# nrf5340 register map
Vendor: Nordic Semiconductor; Series: nrf53; File version: 1
CPU: CM33 r0p2, little endian, MPU, FPU, 3 interrupt priority bits
Registers are 32-bit, read-write, reset 0x0 unless marked. A register's access mark holds for its fields unless they carry their own. Offsets are from the block's base; [hi:lo] are bit positions; lines under a group give offsets from that group; {n}, {i} and the like mark numbered series; 'fields as' and 'values as' point back to an identical list.

## M2M_NS — Memory to Memory DMA 0
Base 0x4002E000
Same registers: M2M_S 0x5002E000
0x00 TASKS_START wo — Start DMA transfer
  [0] TASKS_START
    1=Trigger task
0x04 TASKS_STOP wo — Stop DMA transfer
  [0] TASKS_STOP
    1=Trigger task
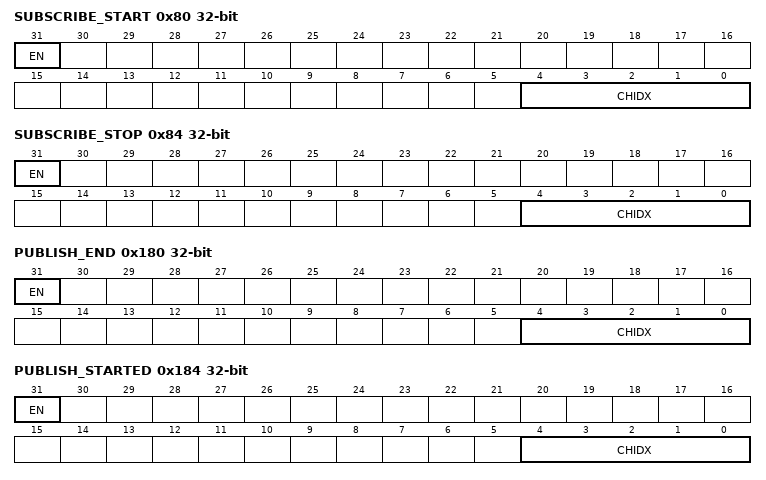
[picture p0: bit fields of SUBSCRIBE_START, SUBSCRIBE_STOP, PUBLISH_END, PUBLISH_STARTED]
0x80 SUBSCRIBE_START — Subscribe configuration for task START
  [31] EN
    0=Disabled (Disable subscription); 1=Enabled (Enable subscription)
  [4:0] CHIDX — Channel that task START will subscribe to
0x84 SUBSCRIBE_STOP — Subscribe configuration for task STOP
  [31] EN
    values as SUBSCRIBE_START.EN
  [4:0] CHIDX — Channel that task STOP will subscribe to
0x100 EVENTS_END — DMA transfer complete
  [0] EVENTS_END
    0=NotGenerated (Event not generated); 1=Generated (Event generated)
0x104 EVENTS_STARTED — DMA transfer started
  [0] EVENTS_STARTED
    values as EVENTS_END.EVENTS_END
0x180 PUBLISH_END — Publish configuration for event END
  [31] EN
    0=Disabled (Disable publishing); 1=Enabled (Enable publishing)
  [4:0] CHIDX — Channel that event END will publish to.
0x184 PUBLISH_STARTED — Publish configuration for event STARTED
  [31] EN
    values as PUBLISH_END.EN
  [4:0] CHIDX — Channel that event STARTED will publish to.
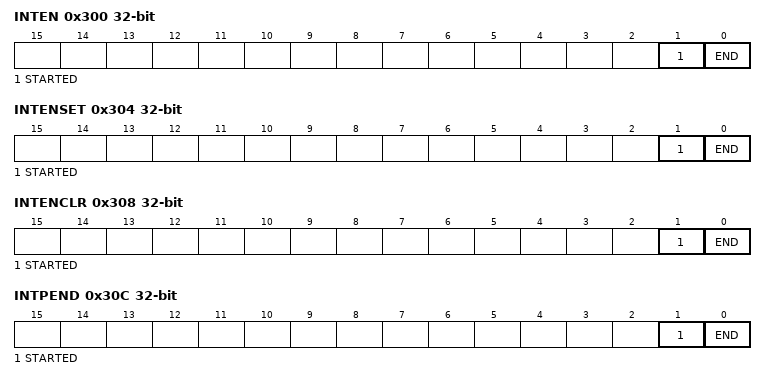
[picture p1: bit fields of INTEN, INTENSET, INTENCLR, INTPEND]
0x300 INTEN — Enable or disable interrupt
  [1] STARTED — Enable or disable interrupt for event STARTED
    0=Disabled; 1=Enabled
  [0] END — Enable or disable interrupt for event END
    0=Disabled; 1=Enabled
0x304 INTENSET — Enable interrupt
  [1] STARTED — Write '1' to enable interrupt for event STARTED
    on read: 0=Disabled (Read: Disabled); 1=Enabled (Read: Enabled) | on write: 1=Set (Enable)
  [0] END — Write '1' to enable interrupt for event END
    values as STARTED
0x308 INTENCLR — Disable interrupt
  [1] STARTED — Write '1' to disable interrupt for event STARTED
    on read: 0=Disabled (Read: Disabled); 1=Enabled (Read: Enabled) | on write: 1=Clear (Disable)
  [0] END — Write '1' to disable interrupt for event END
    values as STARTED
0x30C INTPEND ro — Pending interrupts
  [1] STARTED — Read pending status of interrupt for event STARTED
    on read: 0=NotPending (Read: Not pending); 1=Pending (Read: Pending)
  [0] END — Read pending status of interrupt for event END
    values as STARTED
0x510 IN group — Memory to memory input channel
  0x00 PTR — Data pointer
  0x04 MAXCNT — Maximum number of bytes in input and output buffer
    [15:0] MAXCNT
  0x08 AMOUNT ro — Number of bytes transferred in the last transaction
    [15:0] AMOUNT
  0x0C LIST — EasyDMA list type
    [2:0] LIST — List type
      0=Disabled (Disable EasyDMA list); 1=ArrayList (Use array list)
0x520 OUT group — Memory to memory output channel
  0x00 PTR — Data pointer
  0x04 AMOUNT ro — Number of bytes transferred in the last transaction
    [15:0] AMOUNT
  0x08 LIST — EasyDMA list type
    fields as IN.LIST

## MUTEX_NS — MUTEX 0
Base 0x40030000
Same registers: MUTEX_S 0x50030000
{0x400+4i} MUTEX[{i}] (i=0..15) group — Unspecified
  0x00 GPMUTEX — Description cluster: General purpose mutex register
    [0] GPMUTEX — General Purpose register for MUTEX n
      0=Unlocked (Mutex n is in unlocked state); 1=Locked (Mutex n is in locked state)

## KMU_S — Key Management Unit
Base 0x50080000
0x00 TASKS_PUSH_KEYSLOT wo — Push a key slot over secure APB.
  [0] TASKS_PUSH_KEYSLOT
    1=Trigger task
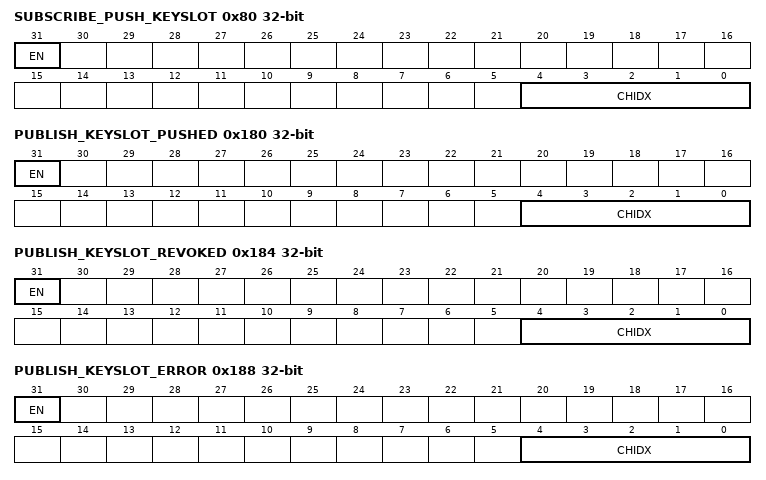
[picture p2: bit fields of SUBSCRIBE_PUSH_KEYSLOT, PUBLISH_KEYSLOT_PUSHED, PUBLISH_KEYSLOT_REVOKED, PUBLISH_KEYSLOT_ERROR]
0x80 SUBSCRIBE_PUSH_KEYSLOT — Subscribe configuration for task PUSH_KEYSLOT
  [31] EN
    0=Disabled (Disable subscription); 1=Enabled (Enable subscription)
  [4:0] CHIDX — Channel that task PUSH_KEYSLOT will subscribe to
0x100 EVENTS_KEYSLOT_PUSHED — Key successfully pushed over secure APB.
  [0] EVENTS_KEYSLOT_PUSHED
    0=NotGenerated (Event not generated); 1=Generated (Event generated)
0x104 EVENTS_KEYSLOT_REVOKED — Key has been revoked and cannot be tasked for selection.
  [0] EVENTS_KEYSLOT_REVOKED
    values as EVENTS_KEYSLOT_PUSHED.EVENTS_KEYSLOT_PUSHED
0x108 EVENTS_KEYSLOT_ERROR — No key slot selected or no destination address defined or error during push mechanism.
  [0] EVENTS_KEYSLOT_ERROR
    values as EVENTS_KEYSLOT_PUSHED.EVENTS_KEYSLOT_PUSHED
0x180 PUBLISH_KEYSLOT_PUSHED — Publish configuration for event KEYSLOT_PUSHED
  [31] EN
    0=Disabled (Disable publishing); 1=Enabled (Enable publishing)
  [4:0] CHIDX — Channel that event KEYSLOT_PUSHED will publish to.
0x184 PUBLISH_KEYSLOT_REVOKED — Publish configuration for event KEYSLOT_REVOKED
  [31] EN
    values as PUBLISH_KEYSLOT_PUSHED.EN
  [4:0] CHIDX — Channel that event KEYSLOT_REVOKED will publish to.
0x188 PUBLISH_KEYSLOT_ERROR — Publish configuration for event KEYSLOT_ERROR
  [31] EN
    values as PUBLISH_KEYSLOT_PUSHED.EN
  [4:0] CHIDX — Channel that event KEYSLOT_ERROR will publish to.
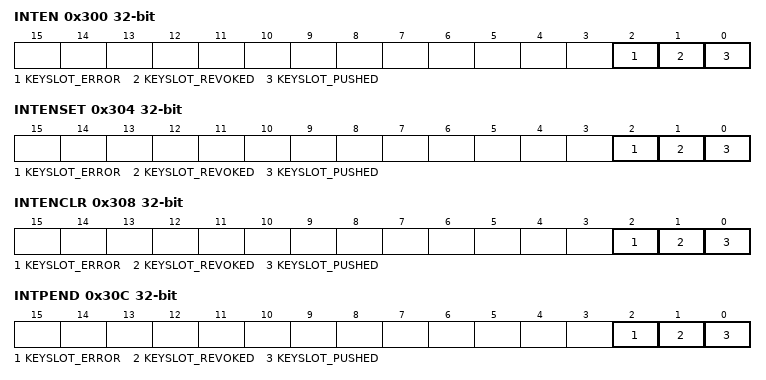
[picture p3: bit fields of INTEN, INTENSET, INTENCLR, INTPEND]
0x300 INTEN — Enable or disable interrupt
  [all] fields
    0=Disabled; 1=Enabled
  [2] KEYSLOT_ERROR — Enable or disable interrupt for event KEYSLOT_ERROR
  [1] KEYSLOT_REVOKED — Enable or disable interrupt for event KEYSLOT_REVOKED
  [0] KEYSLOT_PUSHED — Enable or disable interrupt for event KEYSLOT_PUSHED
0x304 INTENSET — Enable interrupt
  [all] fields
    on read: 0=Disabled (Read: Disabled); 1=Enabled (Read: Enabled) | on write: 1=Set (Enable)
  [2] KEYSLOT_ERROR — Write '1' to enable interrupt for event KEYSLOT_ERROR
  [1] KEYSLOT_REVOKED — Write '1' to enable interrupt for event KEYSLOT_REVOKED
  [0] KEYSLOT_PUSHED — Write '1' to enable interrupt for event KEYSLOT_PUSHED
0x308 INTENCLR — Disable interrupt
  [all] fields
    on read: 0=Disabled (Read: Disabled); 1=Enabled (Read: Enabled) | on write: 1=Clear (Disable)
  [2] KEYSLOT_ERROR — Write '1' to disable interrupt for event KEYSLOT_ERROR
  [1] KEYSLOT_REVOKED — Write '1' to disable interrupt for event KEYSLOT_REVOKED
  [0] KEYSLOT_PUSHED — Write '1' to disable interrupt for event KEYSLOT_PUSHED
0x30C INTPEND ro — Pending interrupts
  [all] fields
    on read: 0=NotPending (Read: Not pending); 1=Pending (Read: Pending)
  [2] KEYSLOT_ERROR — Read pending status of interrupt for event KEYSLOT_ERROR
  [1] KEYSLOT_REVOKED — Read pending status of interrupt for event KEYSLOT_REVOKED
  [0] KEYSLOT_PUSHED — Read pending status of interrupt for event KEYSLOT_PUSHED
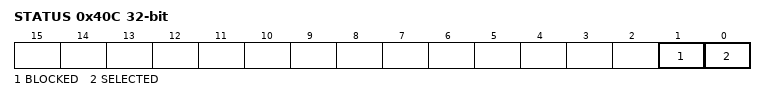
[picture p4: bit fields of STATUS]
0x40C STATUS ro — Status bits for KMU operation.
  [1] BLOCKED — Violation status
    0=Disabled (No access violation detected.); 1=Enabled (Access violation detected and blocked.)
  [0] SELECTED — Key slot ID successfully selected by the KMU.
    0=Disabled (No key slot ID selected by KMU); 1=Enabled (Key slot ID successfully selected by KMU)
0x500 SELECTKEYSLOT — Select key slot ID to be read over AHB or pushed over secure APB when TASKS_PUSH_KEYSLOT is started.
  [7:0] ID

## VMC_NS — Volatile Memory controller 0
Base 0x40081000
Same registers: VMC_S 0x50081000
{0x600+0x10*i} RAM[{i}] (i=0..7) group — Unspecified
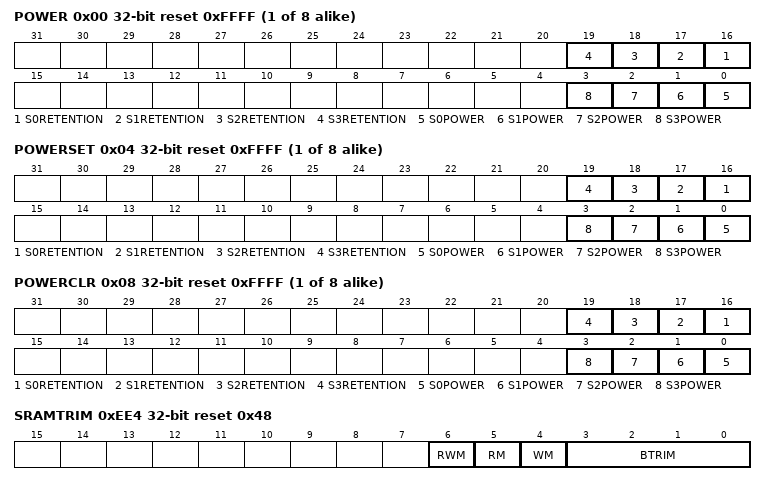
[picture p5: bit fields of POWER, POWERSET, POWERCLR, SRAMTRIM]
  0x00 POWER reset 0xFFFF — Description cluster: RAMn power control register
    [all] fields
      0=Off; 1=On
    [n+16] S{n}RETENTION (n=0..3) — Keep retention on RAM section S{n} of RAM n when RAM section is switched off
    [n] S{n}POWER (n=0..3) — Keep RAM section S{n} of RAM n on or off in System ON mode
  0x04 POWERSET wo reset 0xFFFF — Description cluster: RAMn power control set register
    [all] fields
      1=On
    [n+16] S{n}RETENTION (n=0..3) — Keep retention on RAM section S{n} of RAM n when RAM section is switched off
    [n] S{n}POWER (n=0..3) — Keep RAM section S{n} of RAM n on or off in System ON mode
  0x08 POWERCLR wo reset 0xFFFF — Description cluster: RAMn power control clear register
    [all] fields
      1=Off
    [n+16] S{n}RETENTION (n=0..3) — Keep retention on RAM section S{n} of RAM n when RAM section is switched off
    [n] S{n}POWER (n=0..3) — Keep RAM section S{n} of RAM n on or off in System ON mode
0xEE4 SRAMTRIM reset 0x48 — Backdoor trim values for SRAM
  [6] RWM — Read/Write Margin Adjustment
    0=Disabled; 1=Enabled
  [5] RM — Read Margin Adjustment
    0=Disabled; 1=Enabled
  [4] WM — Write Margin Adjustment
    0=Disabled; 1=Enabled
  [3:0] BTRIM — Source Bias Trim Adjustment for retention
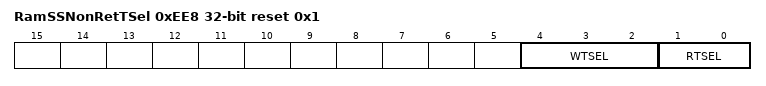
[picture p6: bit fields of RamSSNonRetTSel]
0xEE8 RamSSNonRetTSel reset 0x1 — Timing control values for TSMC RAMs
  [4:2] WTSEL — Write cycle timing selection
  [1:0] RTSEL — Read cycle timing selection

## CRYPTOCELL_S — ARM TrustZone CryptoCell register interface
Base 0x508C1000
0x500 ENABLE — Control power and clock for CRYPTOCELL subsystem
  [0] ENABLE — Enable or disable the CRYPTOCELL subsystem
    0=Disabled (CRYPTOCELL subsystem disabled); 1=Enabled (CRYPTOCELL subsystem enabled)
0x504 RESET — Perform an external reset of the CRYPTOCELL subsystem.
  [0] RESET — Reset CRYPTOCELL subsystem
    0=Disabled (CRYPTOCELL subsystem normal operation); 1=Enabled (Perform CRYPTOCELL subsystem reset)
0x508 IRQ_STATUS ro — Holds the interrupt status from the CRYPTOCELL subsystems.
  [0] IRQ_STATUS — A read will return the current status of the CRYPTOCELL interrupt signal
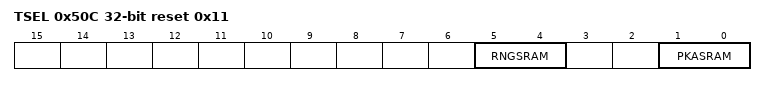
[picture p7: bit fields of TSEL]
0x50C TSEL reset 0x11 — Timing select (TSEL) settings for CRYPTOCELL dedicated PKA and RNG SRAM blocks.
  [5:4] RNGSRAM — Control timing for RNG SRAM block
  [1:0] PKASRAM — Control timing for PKA SRAM block
